VERSION ""

NS_ :

BS_:

BU_: LAS GW mADC

BO_ 3221225472 VECTOR__INDEPENDENT_SIG_MSG: 0 Vector__XXX
 SG_ adasSettings : 0|8@1+ (1,0) [0|255] "" Vector__XXX
 SG_ parkingBrake : 0|1@1+ (1,0) [0|1] "" Vector__XXX
 SG_ rdyDrive : 0|1@1+ (1,0) [0|1] "" Vector__XXX
 SG_ longAccel : 0|16@1+ (0.001,-32.768) [-32.768|32.767] "m/s2" Vector__XXX
 SG_ latAccel : 0|16@1+ (0.001,-32.768) [-32.768|32.767] "m/s2" Vector__XXX
 SG_ espEn : 0|1@1+ (1,0) [0|1] "" Vector__XXX
 SG_ absEn : 0|1@1+ (1,0) [0|1] "" Vector__XXX
 SG_ tracCtrlEn : 0|1@1+ (1,0) [0|1] "" Vector__XXX
 SG_ stabCtrlEn : 0|1@1+ (1,0) [0|1] "" Vector__XXX

BO_ 1760 _0x6E0_userCommand: 8 Vector__XXX
 SG_ counter : 60|4@1+ (1,0) [0|15] "" Vector__XXX
 SG_ brkPedal : 0|8@1+ (0.4,0) [0|102] "%" Vector__XXX
 SG_ accPedal : 8|8@1+ (0.4,0) [0|102] "%" Vector__XXX
 SG_ steerAngle : 16|16@1+ (0.1,-3276.8) [-3276.8|3276.7] "deg" Vector__XXX
 SG_ SteerYawRate : 32|12@1+ (0.01,-81.92) [-81.92|81.91] "deg/s" Vector__XXX
 SG_ btnCcEn : 44|1@1+ (1,0) [0|1] "" Vector__XXX
 SG_ btnLaneEn : 45|1@1+ (1,0) [0|1] "" Vector__XXX
 SG_ btnMads : 56|1@1+ (1,0) [0|1] "" Vector__XXX
 SG_ btnCcSet : 48|1@1+ (1,0) [0|1] "" Vector__XXX
 SG_ btnCcCancel : 49|1@1+ (1,0) [0|1] "" Vector__XXX
 SG_ btnCcResume : 50|1@1+ (1,0) [0|1] "" Vector__XXX
 SG_ btnSpdUp : 51|1@1+ (1,0) [0|1] "" Vector__XXX
 SG_ btnSpdDn : 52|1@1+ (1,0) [0|1] "" Vector__XXX
 SG_ btnDistNr : 46|1@1+ (1,0) [0|1] "" Vector__XXX
 SG_ btnDistFar : 47|1@1+ (1,0) [0|1] "" Vector__XXX
 SG_ btnHazard : 57|1@1+ (1,0) [0|1] "" Vector__XXX
 SG_ btnBlinkL : 58|1@1+ (1,0) [0|1] "" Vector__XXX
 SG_ btnBlinkR : 59|1@1+ (1,0) [0|1] "" Vector__XXX
 SG_ actPedalPressed : 54|1@1+ (1,0) [0|1] "" Vector__XXX
 SG_ actBrakePressed : 55|1@1+ (1,0) [0|1] "" Vector__XXX
 SG_ actSteerPressed : 53|1@1+ (1,0) [0|1] "" Vector__XXX

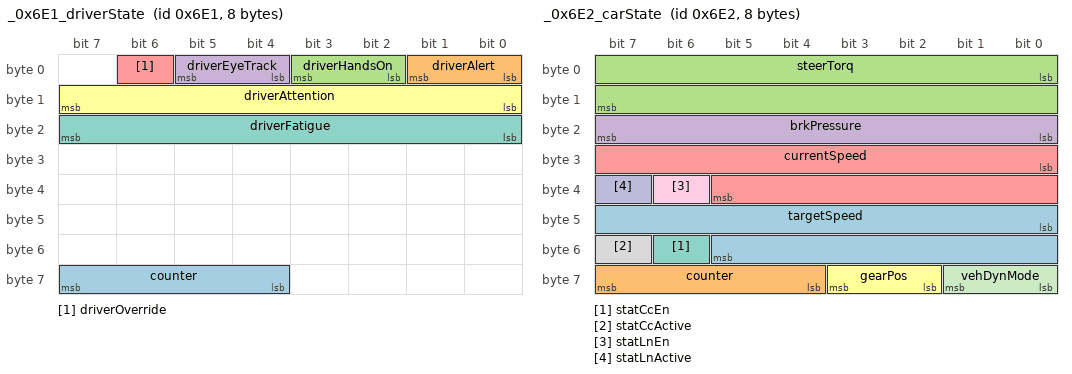
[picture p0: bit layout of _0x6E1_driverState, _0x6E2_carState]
BO_ 1761 _0x6E1_driverState: 8 Vector__XXX
 SG_ counter : 60|4@1+ (1,0) [0|15] "" Vector__XXX
 SG_ driverAlert : 0|2@1+ (1,0) [0|3] "" Vector__XXX
 SG_ driverHandsOn : 2|2@1+ (1,0) [0|3] "" Vector__XXX
 SG_ driverEyeTrack : 4|2@1+ (1,0) [0|3] "" Vector__XXX
 SG_ driverOverride : 6|1@1+ (1,0) [0|1] "" Vector__XXX
 SG_ driverAttention : 8|8@1+ (0.4,0) [0|102] "%" Vector__XXX
 SG_ driverFatigue : 16|8@1+ (0.4,0) [0|102] "%" Vector__XXX

BO_ 1762 _0x6E2_carState: 8 Vector__XXX
 SG_ targetSpeed : 40|14@1+ (0.1,0) [0|409.5] "km/h" Vector__XXX
 SG_ counter : 60|4@1+ (1,0) [0|15] "" Vector__XXX
 SG_ steerTorq : 0|16@1+ (0.1,-3276.8) [-3276.8|3276.7] "Nm" Vector__XXX
 SG_ brkPressure : 16|8@1+ (0.1,0) [0|25.5] "bar" Vector__XXX
 SG_ currentSpeed : 24|14@1+ (0.05625,0) [0|360] "km/h" Vector__XXX
 SG_ gearPos : 58|2@1+ (1,0) [0|7] "" Vector__XXX
 SG_ statCcEn : 54|1@1+ (1,0) [0|1] "" Vector__XXX
 SG_ statCcActive : 55|1@1+ (1,0) [0|1] "" Vector__XXX
 SG_ statLnEn : 38|1@1+ (1,0) [0|1] "" Vector__XXX
 SG_ statLnActive : 39|1@1+ (1,0) [0|1] "" Vector__XXX
 SG_ vehDynMode : 56|2@1+ (1,0) [0|3] "" Vector__XXX

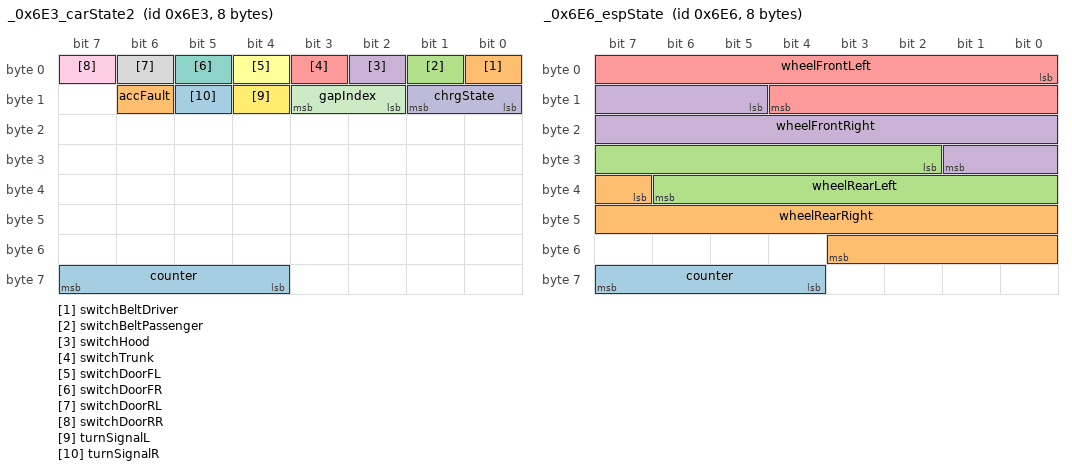
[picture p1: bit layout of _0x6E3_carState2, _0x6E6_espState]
BO_ 1763 _0x6E3_carState2: 8 Vector__XXX
 SG_ counter : 60|4@1+ (1,0) [0|15] "" Vector__XXX
 SG_ switchBeltDriver : 0|1@1+ (1,0) [0|1] "" Vector__XXX
 SG_ switchBeltPassenger : 1|1@1+ (1,0) [0|1] "" Vector__XXX
 SG_ switchHood : 2|1@1+ (1,0) [0|1] "" Vector__XXX
 SG_ switchTrunk : 3|1@1+ (1,0) [0|1] "" Vector__XXX
 SG_ switchDoorFL : 4|1@1+ (1,0) [0|1] "" Vector__XXX
 SG_ switchDoorFR : 5|1@1+ (1,0) [0|1] "" Vector__XXX
 SG_ switchDoorRL : 6|1@1+ (1,0) [0|1] "" Vector__XXX
 SG_ switchDoorRR : 7|1@1+ (1,0) [0|1] "" Vector__XXX
 SG_ chrgState : 8|2@1+ (1,0) [0|3] "" Vector__XXX
 SG_ gapIndex : 10|2@1+ (1,1) [1|4] "" Vector__XXX
 SG_ turnSignalL : 12|1@1+ (1,0) [0|1] "" Vector__XXX
 SG_ turnSignalR : 13|1@1+ (1,0) [0|1] "" Vector__XXX
 SG_ accFault : 14|1@1+ (1,0) [0|1] "" Vector__XXX

BO_ 1766 _0x6E6_espState: 8 Vector__XXX
 SG_ counter : 60|4@1+ (1,0) [0|15] "" Vector__XXX
 SG_ wheelRearRight : 39|13@1+ (0.05625,0) [0|360] "km/h" Vector__XXX
 SG_ wheelRearLeft : 26|13@1+ (0.05625,0) [0|360] "km/h" Vector__XXX
 SG_ wheelFrontRight : 13|13@1+ (0.05625,0) [0|360] "km/h" Vector__XXX
 SG_ wheelFrontLeft : 0|13@1+ (0.05625,0) [0|360] "km/h" Vector__XXX

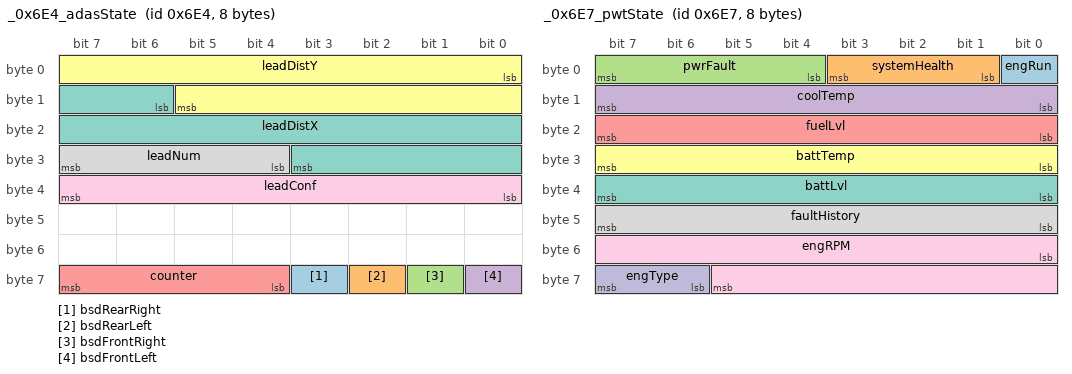
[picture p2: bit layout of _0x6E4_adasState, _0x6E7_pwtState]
BO_ 1764 _0x6E4_adasState: 8 Vector__XXX
 SG_ bsdRearRight : 59|1@1+ (1,0) [0|1] "" Vector__XXX
 SG_ bsdRearLeft : 58|1@1+ (1,0) [0|1] "" Vector__XXX
 SG_ bsdFrontRight : 57|1@1+ (1,0) [0|1] "" Vector__XXX
 SG_ bsdFrontLeft : 56|1@1+ (1,0) [0|1] "" Vector__XXX
 SG_ counter : 60|4@1+ (1,0) [0|15] "" Vector__XXX
 SG_ leadDistY : 0|14@1+ (0.04,0) [0|655.32] "m" Vector__XXX
 SG_ leadDistX : 14|14@1+ (0.04,0) [0|655.32] "m" Vector__XXX
 SG_ leadNum : 28|4@1+ (1,0) [0|3] "" Vector__XXX
 SG_ leadConf : 32|8@1+ (0.4,0) [0|102] "%" Vector__XXX

BO_ 1765 _0x6E5_adasState2: 8 Vector__XXX

BO_ 1767 _0x6E7_pwtState: 8 Vector__XXX
 SG_ engRun : 0|1@1+ (1,0) [0|1] "" Vector__XXX
 SG_ systemHealth : 1|3@1+ (1,0) [0|7] "" Vector__XXX
 SG_ pwrFault : 4|4@1+ (1,0) [0|15] "" Vector__XXX
 SG_ coolTemp : 8|8@1+ (1,-40) [-40|215] "C" Vector__XXX
 SG_ fuelLvl : 16|8@1+ (0.4,0) [0|102] "%" Vector__XXX
 SG_ battTemp : 24|8@1+ (1,-40) [-40|215] "C" Vector__XXX
 SG_ battLvl : 32|8@1+ (0.4,0) [0|102] "%" Vector__XXX
 SG_ faultHistory : 40|8@1+ (1,0) [0|255] "" Vector__XXX
 SG_ engRPM : 48|14@1+ (0.25,0) [0|4095.75] "rpm" Vector__XXX
 SG_ engType : 62|2@1+ (1,0) [0|3] "" Vector__XXX

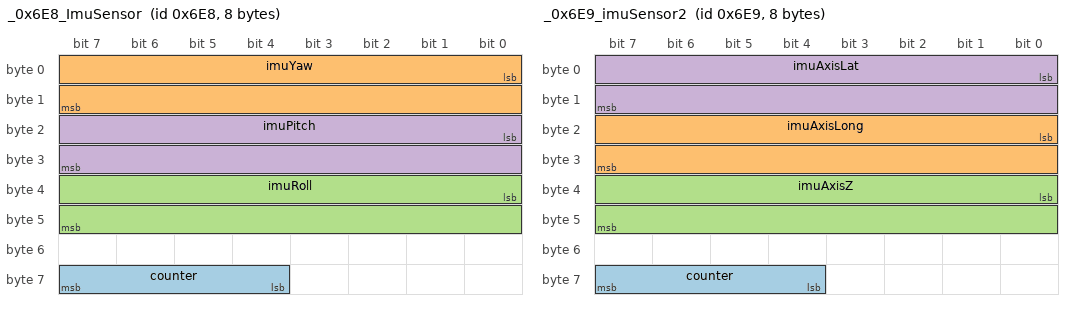
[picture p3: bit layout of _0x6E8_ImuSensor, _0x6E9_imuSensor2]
BO_ 1768 _0x6E8_ImuSensor: 8 Vector__XXX
 SG_ counter : 60|4@1+ (1,0) [0|15] "" Vector__XXX
 SG_ imuYaw : 0|16@1+ (0.015,-491.512) [-491.512|491.513] "deg/s" Vector__XXX
 SG_ imuRoll : 32|16@1+ (0.015,-491.512) [-491.512|491.513] "deg/s" Vector__XXX
 SG_ imuPitch : 16|16@1+ (0.015,-491.512) [-491.512|491.513] "deg/s" Vector__XXX

BO_ 1769 _0x6E9_imuSensor2: 8 Vector__XXX
 SG_ counter : 60|4@1+ (1,0) [0|15] "" Vector__XXX
 SG_ imuAxisLong : 16|16@1+ (0.001,-32.768) [-32.768|32.767] "m/s2" Vector__XXX
 SG_ imuAxisZ : 32|16@1+ (0.001,-32.768) [-32.768|32.767] "m/s2" Vector__XXX
 SG_ imuAxisLat : 0|16@1+ (0.001,-32.768) [-32.768|32.767] "m/s2" Vector__XXX

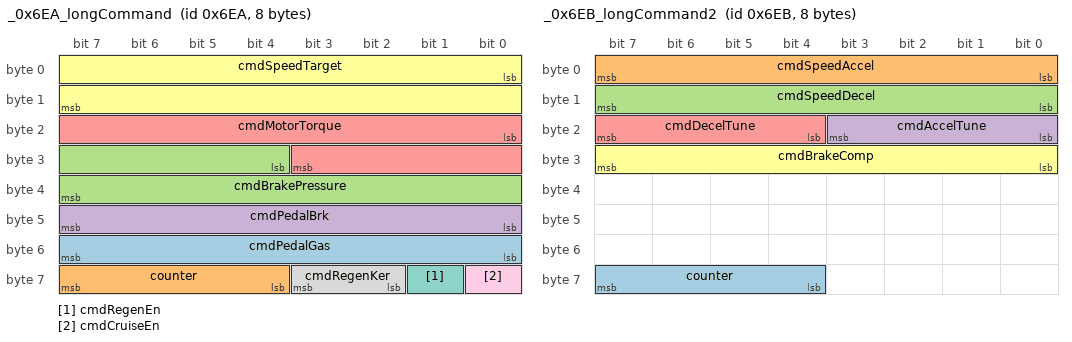
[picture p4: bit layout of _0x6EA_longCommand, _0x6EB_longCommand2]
BO_ 1770 _0x6EA_longCommand: 8 Vector__XXX
 SG_ cmdPedalGas : 48|8@1+ (0.4,0) [0|102] "%" Vector__XXX
 SG_ counter : 60|4@1+ (1,0) [0|15] "" Vector__XXX
 SG_ cmdBrakePressure : 28|12@1+ (0.015625,0) [0|63.984375] "bar" Vector__XXX
 SG_ cmdPedalBrk : 40|8@1+ (0.4,0) [0|102] "%" Vector__XXX
 SG_ cmdMotorTorque : 16|12@1+ (5,-20480) [-20480|-5005] "NM" Vector__XXX
 SG_ cmdSpeedTarget : 0|16@1+ (0.01,0) [0|655.35] "km/h" Vector__XXX
 SG_ cmdRegenEn : 57|1@1+ (1,0) [0|1] "" Vector__XXX
 SG_ cmdRegenKer : 58|2@1+ (1,0) [0|3] "" Vector__XXX
 SG_ cmdCruiseEn : 56|1@1+ (1,0) [0|1] "" Vector__XXX

BO_ 1771 _0x6EB_longCommand2: 8 Vector__XXX
 SG_ counter : 60|4@1+ (1,0) [0|15] "" Vector__XXX
 SG_ cmdSpeedAccel : 0|8@1+ (0.05,-12.8) [-12.8|-0.05] "m/s2" Vector__XXX
 SG_ cmdSpeedDecel : 8|8@1+ (0.05,-12.8) [-12.8|-0.05] "m/s2" Vector__XXX
 SG_ cmdAccelTune : 16|4@1+ (1,0) [0|15] "" Vector__XXX
 SG_ cmdDecelTune : 20|4@1+ (1,0) [0|15] "" Vector__XXX
 SG_ cmdBrakeComp : 24|8@1+ (0.0039216,0) [0|1] "" Vector__XXX

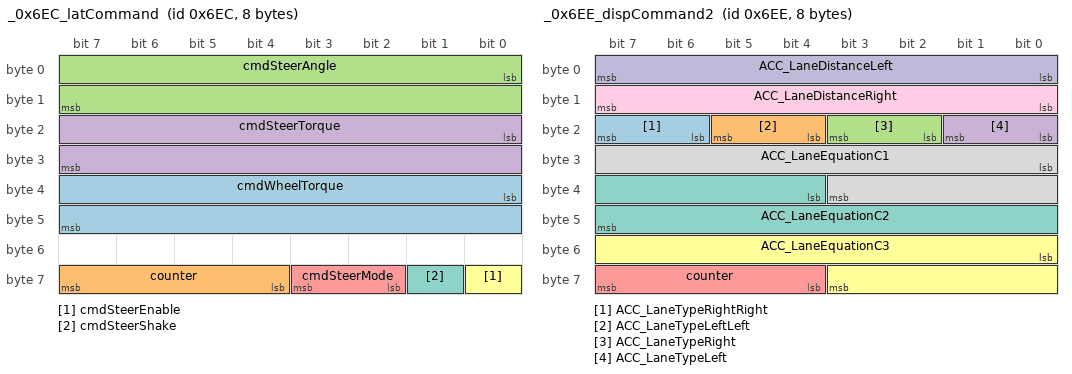
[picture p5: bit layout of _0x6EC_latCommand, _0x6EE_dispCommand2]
BO_ 1772 _0x6EC_latCommand: 8 Vector__XXX
 SG_ cmdWheelTorque : 32|16@1+ (0.1,-3276.8) [-3276.8|3276.7] "Nm" Vector__XXX
 SG_ counter : 60|4@1+ (1,0) [0|15] "" Vector__XXX
 SG_ cmdSteerAngle : 0|16@1+ (0.1,-3276.8) [-3276.8|3276.7] "deg" Vector__XXX
 SG_ cmdSteerTorque : 16|16@1+ (0.01,-327.68) [-327.68|327.67] "Nm" Vector__XXX
 SG_ cmdSteerMode : 58|2@1+ (1,0) [0|3] "" Vector__XXX
 SG_ cmdSteerEnable : 56|1@1+ (1,0) [0|1] "" Vector__XXX
 SG_ cmdSteerShake : 57|1@1+ (1,0) [0|1] "" Vector__XXX

BO_ 1773 _0x6ED_dispCommand: 8 Vector__XXX
 SG_ cmdDispFCW : 18|1@1+ (1,0) [0|1] "" Vector__XXX
 SG_ cmdDispDistraction : 19|1@1+ (1,0) [0|1] "" Vector__XXX
 SG_ cmdDispMoving : 17|1@1+ (1,0) [0|1] "" Vector__XXX
 SG_ cmdDispStandStill : 16|1@1+ (1,0) [0|1] "" Vector__XXX
 SG_ cmdDispTurnRight : 12|1@1+ (1,0) [0|1] "" Vector__XXX
 SG_ cmdDispTurnLeft : 11|1@1+ (1,0) [0|1] "" Vector__XXX
 SG_ cmdDispLeadNumber : 20|4@1+ (1,0) [0|15] "" Vector__XXX
 SG_ cmdDispLeadLong : 48|12@1+ (0.1,0) [0|409.5] "m" Vector__XXX
 SG_ cmdDispLeadLat : 40|8@1+ (0.1,-12.75) [-12.75|12.75] "m" Vector__XXX
 SG_ cmdDispBsdRight : 10|1@1+ (1,0) [0|1] "" Vector__XXX
 SG_ cmdDispBsdLeft : 9|1@1+ (1,0) [0|1] "" Vector__XXX
 SG_ cmdSteerAlert : 6|2@1+ (1,0) [0|3] "" Vector__XXX
 SG_ counter : 60|4@1+ (1,0) [0|15] "" Vector__XXX
 SG_ cmdDispCcEn : 0|1@1+ (1,0) [0|1] "" Vector__XXX
 SG_ cmdDispCcActive : 1|1@1+ (1,0) [0|1] "" Vector__XXX
 SG_ cmdDispLnEn : 2|1@1+ (1,0) [0|1] "" Vector__XXX
 SG_ cmdDispLnActive : 3|1@1+ (1,0) [0|1] "" Vector__XXX
 SG_ cmdDispSoundAlert : 8|1@1+ (1,0) [0|1] "" Vector__XXX
 SG_ cmdDispDepartLeft : 4|1@1+ (1,0) [0|1] "" Vector__XXX
 SG_ cmdDispDepartRight : 5|1@1+ (1,0) [0|1] "" Vector__XXX
 SG_ cmdDispFollowDistance : 13|3@1+ (1,0) [0|7] "" Vector__XXX
 SG_ cmdDispSpeed : 24|16@1+ (0.01,0) [0|655.35] "km/h" Vector__XXX

BO_ 1774 _0x6EE_dispCommand2: 8 Vector__XXX
 SG_ ACC_LaneTypeRightRight : 22|2@1+ (1,0) [0|3] "" Vector__XXX
 SG_ ACC_LaneTypeLeftLeft : 20|2@1+ (1,0) [0|3] "" Vector__XXX
 SG_ ACC_LaneTypeRight : 18|2@1+ (1,0) [0|3] "" Vector__XXX
 SG_ ACC_LaneTypeLeft : 16|2@1+ (1,0) [0|3] "" Vector__XXX
 SG_ counter : 60|4@1+ (1,0) [0|15] "" Vector__XXX
 SG_ ACC_LaneEquationC3 : 48|12@1+ (4.768E-07,-0.0009760857) [-0.0009760857|0.0009760857] ""  LAS,GW,mADC
 SG_ ACC_LaneEquationC2 : 36|12@1+ (1.52588E-05,-0.0312347412) [-0.0312347412|0.0312347412] ""  LAS,GW,mADC
 SG_ ACC_LaneEquationC1 : 24|12@1+ (0.0004882813,-1) [-1|0.9990234375] "rad"  LAS,GW,mADC
 SG_ ACC_LaneDistanceRight : 8|8@1+ (0.05,-6.375) [-6.375|6.375] "m"  LAS,GW,mADC
 SG_ ACC_LaneDistanceLeft : 0|8@1+ (0.05,-6.375) [-6.375|6.375] "m"  LAS,GW,mADC

BO_ 1775 _0x6EF_spareCommand: 8 Vector__XXX
 SG_ counter : 60|4@1+ (1,0) [0|15] "" Vector__XXX

BO_ 1776 _0x6F0_BYD: 4 Vector__XXX
 SG_ modelMarker : 0|8@1+ (1,0) [0|255] "" Vector__XXX

BO_ 1777 _0x6F1_CHANGAN: 4 Vector__XXX
 SG_ modelMarker : 0|8@1+ (1,0) [0|255] "" Vector__XXX

BO_ 1778 _0x6F2_MG: 8 Vector__XXX
 SG_ modelMarker : 0|8@1+ (1,0) [0|255] "" Vector__XXX

BO_ 1779 _0x6F3_GAC: 8 Vector__XXX
 SG_ modelMarker : 0|8@1+ (1,0) [0|255] "" Vector__XXX

CM_ BO_ 3221225472 "This is a message for not used signals, created by Vector CANdb++ DBC OLE DB Provider.";
